# watchdog register map
Vendor: Texas Instruments
Peripheral module from a debugger description file (folder sc4cc231e6pm).
Registers are 32-bit, read-write, no defined reset value unless marked. A register's access mark holds for its fields unless they carry their own. Offsets are as the file gives them; lines under a group give offsets from that group; [hi:lo] are bit positions; {n}, {i} and the like mark numbered series; 'fields as' and 'values as' point back to an identical list; <NAME> marks a mode.

## WATCHDOG0 — Watchdog Timer register offsets
0x00 WDT_LOAD — Watchdog Load
  [31:0] WDT_LOAD — Watchdog Load Value
0x04 WDT_VALUE ro — Watchdog Value
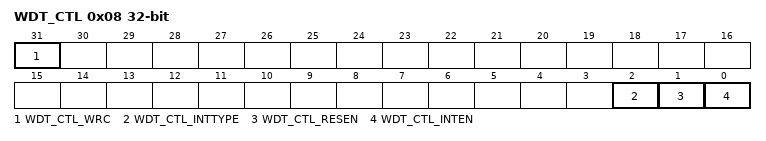
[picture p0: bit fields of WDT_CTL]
0x08 WDT_CTL — Watchdog Control
  [31] WDT_CTL_WRC — Write Complete
  [2] WDT_CTL_INTTYPE — Watchdog Interrupt Type
  [1] WDT_CTL_RESEN — Watchdog Reset Enable
  [0] WDT_CTL_INTEN — Watchdog Interrupt Enable
0x0C WDT_ICR wo — Watchdog Interrupt Clear
0x10 WDT_RIS ro — Watchdog Raw Interrupt Status
  [0] WDT_RIS_WDTRIS
0x14 WDT_MIS ro — Watchdog Masked Interrupt Status
  [0] WDT_MIS_WDTMIS
0x418 WDT_TEST — Watchdog Test
  [8] WDT_TEST_STALL — Watchdog Stall Enable
0xC00 WDT_LOCK — Watchdog Lock
  [31:0] WDT_LOCK
    0=WDT_LOCK_UNLOCKED (Unlocked); 1=WDT_LOCK_LOCKED (Locked); 0x1ACCE551=WDT_LOCK_UNLOCK (Unlocks the watchdog timer)
